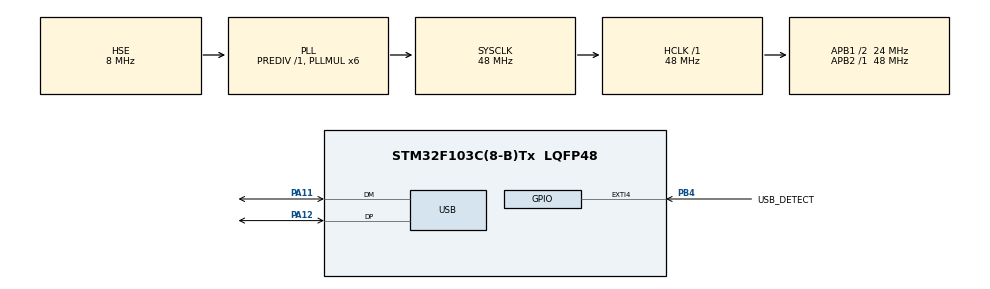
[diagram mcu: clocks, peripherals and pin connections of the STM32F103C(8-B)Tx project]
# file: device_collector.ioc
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Mcu.Family=STM32F1
Mcu.Name=STM32F103C(8-B)Tx
Mcu.Package=LQFP48
NVIC.EXTI4_IRQn=true\:0\:0\:false\:false\:true\:true\:true\:true
NVIC.PriorityGroup=NVIC_PRIORITYGROUP_4
PA11.Mode=Device
PA11.Signal=USB_DM
PA12.Mode=Device
PA12.Signal=USB_DP
PA13.Mode=Serial_Wire
PA13.Signal=SYS_JTMS-SWDIO
PA14.Mode=Serial_Wire
PA14.Signal=SYS_JTCK-SWCLK
PB4.GPIO_Label=USB_DETECT
PB4.GPIO_ModeDefaultEXTI=GPIO_MODE_IT_FALLING
PB4.GPIO_PuPd=GPIO_PULLDOWN
PB4.Signal=GPXTI4
PD0-OSC_IN.Mode=HSE-External-Oscillator
PD0-OSC_IN.Signal=RCC_OSC_IN
PD1-OSC_OUT.Mode=HSE-External-Oscillator
PD1-OSC_OUT.Signal=RCC_OSC_OUT
ProjectManager.HeapSize=0x200
ProjectManager.StackSize=0x400
ProjectManager.TargetToolchain=STM32CubeIDE
RCC.AHBFreq_Value=48000000
RCC.APB1CLKDivider=RCC_HCLK_DIV2
RCC.APB1Freq_Value=24000000
RCC.APB1TimFreq_Value=48000000
RCC.APB2Freq_Value=48000000
RCC.APB2TimFreq_Value=48000000
RCC.EnbaleCSS=true
RCC.HCLKFreq_Value=48000000
RCC.PLLMUL=RCC_PLL_MUL6
RCC.SYSCLKFreq_VALUE=48000000
RCC.SYSCLKSource=RCC_SYSCLKSOURCE_PLLCLK
RCC.USBFreq_Value=48000000
board=custom

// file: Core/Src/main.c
/* USER CODE BEGIN Header */
/**
 ******************************************************************************
 * @file           : main.c
 * @brief          : Main program body
 ******************************************************************************
 * @attention
 *
 * Copyright (c) 2024 STMicroelectronics.
 * All rights reserved.
 *
 * This software is licensed under terms that can be found in the LICENSE file
 * in the root directory of this software component.
 * If no LICENSE file comes with this software, it is provided AS-IS.
 *
 ******************************************************************************
 */
/* USER CODE END Header */
#include "main.h"

/* USER CODE BEGIN Includes */
#include <stdbool.h>
/* USER CODE END Includes */

PCD_HandleTypeDef hpcd_USB_FS;

/* USER CODE BEGIN PV */
// Флаг готовности полученных с хоста данных
extern volatile bool isReceived;
// Структура для сохранения reportId и массива данных
extern struct HIDDataPacket data;

// Отслеживаем разрыв соединения по USB
// Флаг устанавливается в true при сбросе напряжения в 0 на разъёме USB
volatile bool isDisconnected = false;
volatile uint32_t time_exti4 = 0;
/* USER CODE END PV */

void SystemClock_Config(void);
static void MX_GPIO_Init(void);
static void MX_USB_PCD_Init(void);
/* USER CODE BEGIN PFP */
static void isDisconnectUSB(void);
/* USER CODE END PFP */

int main(void)
{

  /* MCU Configuration--------------------------------------------------------*/

  /* Reset of all peripherals, Initializes the Flash interface and the Systick. */
  HAL_Init();

  /* Configure the system clock */
  SystemClock_Config();

  /* Initialize all configured peripherals */
  MX_GPIO_Init();
  MX_USB_PCD_Init();

  /* Infinite loop */
  /* USER CODE BEGIN WHILE */
  while (1) {
    if (isDisconnected && (HAL_GetTick() - time_exti4) > 200) {
      // Произошла потеря питания линии USB
      isDisconnectUSB();
    }
    /* USER CODE END WHILE */

  }
}

void SystemClock_Config(void)
{
  RCC_OscInitTypeDef RCC_OscInitStruct = { 0 };
  RCC_ClkInitTypeDef RCC_ClkInitStruct = { 0 };
  RCC_PeriphCLKInitTypeDef PeriphClkInit = { 0 };

  /** Initializes the RCC Oscillators according to the specified parameters
   * in the RCC_OscInitTypeDef structure.
   */
  RCC_OscInitStruct.OscillatorType = RCC_OSCILLATORTYPE_HSE;
  RCC_OscInitStruct.HSEState = RCC_HSE_ON;
  RCC_OscInitStruct.HSEPredivValue = RCC_HSE_PREDIV_DIV1;
  RCC_OscInitStruct.HSIState = RCC_HSI_ON;
  RCC_OscInitStruct.PLL.PLLState = RCC_PLL_ON;
  RCC_OscInitStruct.PLL.PLLSource = RCC_PLLSOURCE_HSE;
  RCC_OscInitStruct.PLL.PLLMUL = RCC_PLL_MUL6;
  if (HAL_RCC_OscConfig(&RCC_OscInitStruct) != HAL_OK) {
    Error_Handler();
  }

  /** Initializes the CPU, AHB and APB buses clocks
   */
  RCC_ClkInitStruct.ClockType = RCC_CLOCKTYPE_HCLK | RCC_CLOCKTYPE_SYSCLK | RCC_CLOCKTYPE_PCLK1 | RCC_CLOCKTYPE_PCLK2;
  RCC_ClkInitStruct.SYSCLKSource = RCC_SYSCLKSOURCE_PLLCLK;
  RCC_ClkInitStruct.AHBCLKDivider = RCC_SYSCLK_DIV1;
  RCC_ClkInitStruct.APB1CLKDivider = RCC_HCLK_DIV2;
  RCC_ClkInitStruct.APB2CLKDivider = RCC_HCLK_DIV1;

  if (HAL_RCC_ClockConfig(&RCC_ClkInitStruct, FLASH_LATENCY_1) != HAL_OK) {
    Error_Handler();
  }
  PeriphClkInit.PeriphClockSelection = RCC_PERIPHCLK_USB;
  PeriphClkInit.UsbClockSelection = RCC_USBCLKSOURCE_PLL;
  if (HAL_RCCEx_PeriphCLKConfig(&PeriphClkInit) != HAL_OK) {
    Error_Handler();
  }

  /** Enables the Clock Security System
   */
  HAL_RCC_EnableCSS();
}

static void MX_USB_PCD_Init(void)
{

  hpcd_USB_FS.Instance = USB;
  hpcd_USB_FS.Init.dev_endpoints = 8;
  hpcd_USB_FS.Init.speed = PCD_SPEED_FULL;
  hpcd_USB_FS.Init.low_power_enable = DISABLE;
  hpcd_USB_FS.Init.lpm_enable = DISABLE;
  hpcd_USB_FS.Init.battery_charging_enable = DISABLE;
  if (HAL_PCD_Init(&hpcd_USB_FS) != HAL_OK) {
    Error_Handler();
  }

}

static void MX_GPIO_Init(void)
{
  GPIO_InitTypeDef GPIO_InitStruct = { 0 };

  /* GPIO Ports Clock Enable */
  __HAL_RCC_GPIOD_CLK_ENABLE();
  __HAL_RCC_GPIOA_CLK_ENABLE();
  __HAL_RCC_GPIOB_CLK_ENABLE();

  /*Configure GPIO pin : USB_DETECT_Pin */
  GPIO_InitStruct.Pin = USB_DETECT_Pin;
  GPIO_InitStruct.Mode = GPIO_MODE_IT_FALLING;
  GPIO_InitStruct.Pull = GPIO_PULLDOWN;
  HAL_GPIO_Init(USB_DETECT_GPIO_Port, &GPIO_InitStruct);

  /* EXTI interrupt init*/
  HAL_NVIC_SetPriority(EXTI4_IRQn, 0, 0);
  HAL_NVIC_EnableIRQ(EXTI4_IRQn);

}

/* USER CODE BEGIN 4 */
void HAL_GPIO_EXTI_Callback(uint16_t GPIO_Pin)
{
  if (GPIO_Pin == USB_DETECT_Pin) {
    // Сразу же отключаем внешнее прерывания EXTI4
    HAL_NVIC_DisableIRQ(EXTI4_IRQn);
    // Устанавливаем флаг и сохраняем текущее время
    isDisconnected = true;
    time_exti4 = HAL_GetTick();
  }
}

// Функция обработки срабатывания разрыва соединения по USB
static void isDisconnectUSB(void)
{
  // Ожидаем 200 мс для повторной проверки питания линии USB
  if (HAL_GPIO_ReadPin(USB_DETECT_GPIO_Port, USB_DETECT_Pin) == GPIO_PIN_RESET) {
    // На линии USB отсутствует напряжние
    // Сбрасываем флаг
    isDisconnected = false;

    // Проверяем, если таймер запущен сбрасываем его.
  }
  // Запускаем проверку для нового ослеживания разрыва соединения
  // При помощи макроса очищаем бит EXTI_PR
  __HAL_GPIO_EXTI_CLEAR_IT(USB_DETECT_Pin);
  // Очищаем бит NVIC_ICPRx
  NVIC_ClearPendingIRQ(EXTI4_IRQn);
  // Включаем внешнее прерывание
  HAL_NVIC_EnableIRQ(EXTI4_IRQn);
}
/* USER CODE END 4 */

void Error_Handler(void)
{
  __disable_irq();
  while (1) {
  }
}
